# ipro6s register map
Vendor: intelpro; Series: IPRO6S
CPU: ipro6s, little endian
Registers are 32-bit, read-write, reset 0x0 unless marked. A register's access mark holds for its fields unless they carry their own. Offsets are from the block's base; [hi:lo] are bit positions; {n}, {i} and the like mark numbered series; <NAME> marks a mode.

## DBI
Base 0x30016000
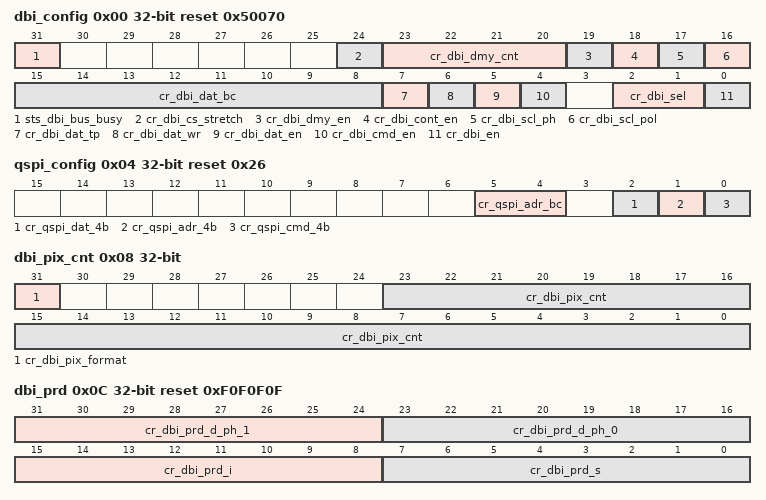
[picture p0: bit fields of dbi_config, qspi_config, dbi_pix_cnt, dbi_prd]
0x00 dbi_config reset 0x50070 (reset mask 0x1FFFFF7)
  [31] sts_dbi_bus_busy ro — Indicator of dbi bus busy
  [24] cr_dbi_cs_stretch — Enable signal of CS-low stretch mode 1'b0: Disabled, if FIFO is empty during a pixel data transfer, CS will de-assert before FIFO is filled again and new transfer starts 1'b1: Enabled, if FIFO is empty during a pixel data transfer, CS will stay asserted while waiting for FIFO to be filled again
  [23:20] cr_dbi_dmy_cnt — Dummy cycle count, unit: period defined by dbi_prd_d Effective only in Type C (Fixed to 1 dbi_prd_d period in Type B)
  [19] cr_dbi_dmy_en — Enable signal of dummy cycle(s) 1'b0: Disabled, no dummy cycle(s) between command phase and data phase 1'b1: Enabled, dummy cycle(s) will be inserted between command phase and data phase Note: Don't-care if QSPI mode is selected (no dummy cycle)
  [18] cr_dbi_cont_en — Enable signal of pixel data continuous transfer mode 1'b0: Disabled, CS_n will de-assert between each pixel 1'b1: Enabled, CS_n will stay asserted between each consecutive pixel Note: Don't-care if QSPI mode is selected (always in continuous mode)
  [17] cr_dbi_scl_ph — SCL clock phase inverse signal
  [16] cr_dbi_scl_pol — SCL clock polarity 0: SCL output LOW at IDLE state 1: SCL output HIGH at IDLE state
  [15:8] cr_dbi_dat_bc — Data byte count of normal data (pixel data count is determined by cr_dbi_pix_cnt) Note: Normal read data can only be up to 8-byte (8'd7). No limit for normal write data (can be up to 256-byte using FIFO)
  [7] cr_dbi_dat_tp — Data type select 1'b0: Normal data (parameter) 1'b1: Pixel data Note: Read command supports normal data only
  [6] cr_dbi_dat_wr — Data phase Read/Write select 1'b0: Read data 1'b1: Write data
  [5] cr_dbi_dat_en — Data enable signal 1'b0: Data phase disabled 1'b1: Data phase enabled
  [4] cr_dbi_cmd_en — Command enable signal 1'b0: No command phase 1'b1: Command will be sent Note: Don't-care if QSPI mode is selected (Command always enabled)
  [2:1] cr_dbi_sel — DBI mode select 2'd0: DBI Type B 2'd1: DBI Type C, 4-wire mode 2'd2: DBI Type C, 3-wire mode 2'd3: QSPI mode
  [0] cr_dbi_en — Enable signal of DBI function Asserting this bit will trigger the transaction, and should be de-asserted after finish
0x04 qspi_config reset 0x26
  [5:4] cr_qspi_adr_bc — QSPI Address byte count
  [2] cr_qspi_dat_4b — QSPI Data 4-bit (quad) mode 1'b0: Data sent/received in 1-bit mode 1'b1: Data sent/received in 4-bit mode
  [1] cr_qspi_adr_4b — QSPI Address (display command) 4-bit (quad) mode 1'b0: Address sent in 1-bit mode 1'b1: Address sent in 4-bit mode
  [0] cr_qspi_cmd_4b — QSPI Command 4-bit (quad) mode 1'b0: Command sent in 1-bit mode 1'b1: Command sent in 4-bit mode
0x08 dbi_pix_cnt
  [31] cr_dbi_pix_format — Pixel format 1'b0: RGB565 1'b1: RGB888/RGB666
  [23:0] cr_dbi_pix_cnt — Pixel count Note: Should be a multiple of 2 if RGB565 is selected and a multiple of 4 if RGB888/RGB666 mode is selected
0x0C dbi_prd reset 0xF0F0F0F
  [31:24] cr_dbi_prd_d_ph_1 — Length of DATA phase 1 (please refer to "Timing" tab)
  [23:16] cr_dbi_prd_d_ph_0 — Length of DATA phase 0 (please refer to "Timing" tab)
  [15:8] cr_dbi_prd_i — Length of INTERVAL between pixel data (please refer to "Timing" tab)
  [7:0] cr_dbi_prd_s — Length of START/STOP condition (please refer to "Timing" tab)
0x10 dbi_cmd reset 0x2C
  [7:0] cr_dbi_cmd — DBI Command
0x14 dbi_qspi_adr reset 0x2C00
  [31:0] cr_qspi_adr — QSPI Address (display command) Note: LSB is sent first
0x18 dbi_rdata_0 reset not defined
  [31:0] sts_dbi_rdata_0 ro — Data read from display IC using read command
0x1C dbi_rdata_1 reset not defined
  [31:0] sts_dbi_rdata_1 ro — Data read from display IC using read command
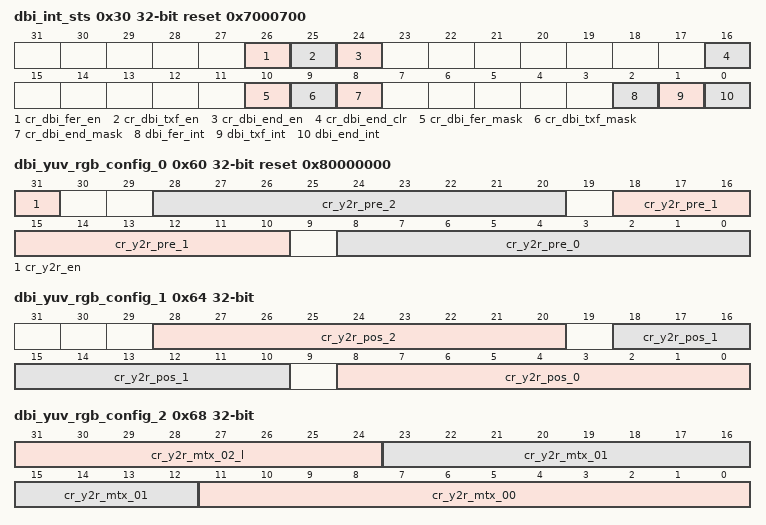
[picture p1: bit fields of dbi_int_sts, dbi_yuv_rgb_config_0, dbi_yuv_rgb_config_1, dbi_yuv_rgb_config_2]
0x30 dbi_int_sts reset 0x7000700 (reset mask 0x7070700)
  [26] cr_dbi_fer_en — Interrupt enable of dbi_fer_int
  [25] cr_dbi_txf_en — Interrupt enable of dbi_txe_int
  [24] cr_dbi_end_en — Interrupt enable of dbi_end_int
  [16] cr_dbi_end_clr wo — Interrupt clear of dbi_end_int
  [10] cr_dbi_fer_mask — Interrupt mask of dbi_fer_int
  [9] cr_dbi_txf_mask — Interrupt mask of dbi_txe_int
  [8] cr_dbi_end_mask — Interrupt mask of dbi_end_int
  [2] dbi_fer_int ro — TX/RX FIFO error interrupt, auto-cleared when FIFO overflow/underflow error flag is cleared
  [1] dbi_txf_int ro — TX FIFO ready (tx_fifo_cnt > tx_fifo_th) interrupt, auto-cleared when data is pushed
  [0] dbi_end_int ro — Transfer end interrupt, shared by both Type B and C mode
0x60 dbi_yuv_rgb_config_0 reset 0x80000000
  [31] cr_y2r_en — Display module YUV2RGB enable signal
  [28:20] cr_y2r_pre_2 — Display module YUV2RGB "pre_offset_2" parameter
  [18:10] cr_y2r_pre_1 — Display module YUV2RGB "pre_offset_1" parameter
  [8:0] cr_y2r_pre_0 — Display module YUV2RGB "pre_offset_0" parameter
0x64 dbi_yuv_rgb_config_1
  [28:20] cr_y2r_pos_2 — Display module YUV2RGB "post_offset_2" parameter
  [18:10] cr_y2r_pos_1 — Display module YUV2RGB "post_offset_1" parameter
  [8:0] cr_y2r_pos_0 — Display module YUV2RGB "post_offset_0" parameter
0x68 dbi_yuv_rgb_config_2
  [31:24] cr_y2r_mtx_02_l — Display module YUV2RGB "matrix_02" parameter lower bits
  [23:12] cr_y2r_mtx_01 — Display module YUV2RGB "matrix_01" parameter
  [11:0] cr_y2r_mtx_00 — Display module YUV2RGB "matrix_00" parameter
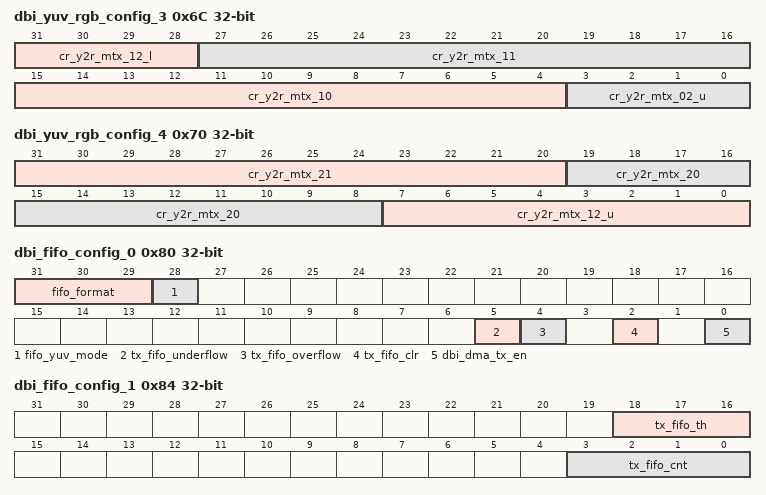
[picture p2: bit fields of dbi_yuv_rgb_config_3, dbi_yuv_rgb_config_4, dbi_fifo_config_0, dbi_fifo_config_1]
0x6C dbi_yuv_rgb_config_3
  [31:28] cr_y2r_mtx_12_l — Display module YUV2RGB "matrix_12" parameter lower bits
  [27:16] cr_y2r_mtx_11 — Display module YUV2RGB "matrix_11" parameter
  [15:4] cr_y2r_mtx_10 — Display module YUV2RGB "matrix_10" parameter
  [3:0] cr_y2r_mtx_02_u — Display module YUV2RGB "matrix_02" parameter upper bits
0x70 dbi_yuv_rgb_config_4
  [31:20] cr_y2r_mtx_21 — Display module YUV2RGB "matrix_21" parameter
  [19:8] cr_y2r_mtx_20 — Display module YUV2RGB "matrix_20" parameter
  [7:0] cr_y2r_mtx_12_u — Display module YUV2RGB "matrix_12" parameter upper bits
0x74 dbi_yuv_rgb_config_5
  [11:0] cr_y2r_mtx_22 — Display module YUV2RGB "matrix_22" parameter
0x80 dbi_fifo_config_0 (reset mask 0xF0000005)
  [31:29] fifo_format — FIFO pixel data format (see Tab 'FIFO Format' for details) 3'd0: {8'h0, B[7:0], G[7:0], R[7:0]} 3'd1: {8'h0, R[7:0], G[7:0], B[7:0]} 3'd2: {B[7:0], G[7:0], R[7:0], 8'h0} 3'd3: {R[7:0], G[7:0], B[7:0], 8'h0} 3'd4: {R_n[7:0], B[7:0], G[7:0], R[7:0]} 3'd5: {B_n[7:0], R[7:0], G[7:0], B[7:0]} 3'd6: {2{B[7:3], G[7:2], R[7:3]}} 3'd7: {2{R[7:3], G[7:2], B[7:3]}} Note: FIFO data format does not affect normal data, which is fixed to LSB sent first {Byte3[7:0], Byte2[7:0], Byte1[7:0], Byte0[7:0]}
  [28] fifo_yuv_mode — FIFO data YUV mode R <-> Y G <-> U/Cb B <-> V/Cr
  [5] tx_fifo_underflow ro — Underflow flag of TX FIFO, can be cleared by tx_fifo_clr
  [4] tx_fifo_overflow ro — Overflow flag of TX FIFO, can be cleared by tx_fifo_clr
  [2] tx_fifo_clr wo — Clear signal of TX FIFO
  [0] dbi_dma_tx_en — Enable signal of dma_tx_req/ack interface
0x84 dbi_fifo_config_1 (reset mask 0x70000)
  [18:16] tx_fifo_th — TX FIFO threshold, dma_tx_req will not be asserted if tx_fifo_cnt is less than this value
  [3:0] tx_fifo_cnt ro — TX FIFO available count
0x88 dbi_fifo_wdata
  [31:0] dbi_fifo_wdata wo — Pixel data with 8 types of format (determined by fifo_format)
0xFC dbi_dummy
  [7:0] dbi_dummy — Dummy register for FPGA mode pad control
